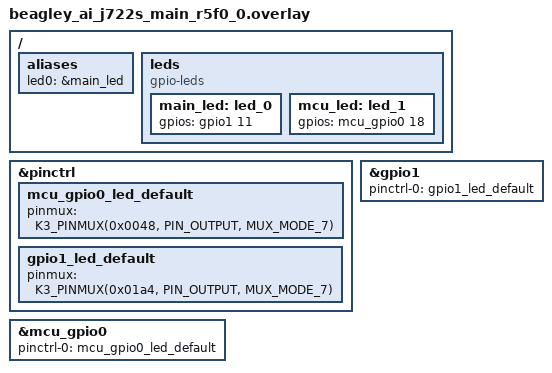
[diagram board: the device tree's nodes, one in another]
/*
 * SPDX-License-Identifier: Apache-2.0
 */

 #include <zephyr/dt-bindings/gpio/gpio.h>

 / {
	aliases {
		led0 = &main_led;
	};

	leds {
		compatible = "gpio-leds";

		main_led: led_0 {
			gpios = <&gpio1 11 GPIO_ACTIVE_HIGH>;
		};

		mcu_led: led_1 {
			gpios = <&mcu_gpio0 18 GPIO_ACTIVE_HIGH>;
		};
	};
};

&pinctrl {
	mcu_gpio0_led_default: mcu_gpio0_led_default {
		pinmux = <K3_PINMUX(0x0048, PIN_OUTPUT, MUX_MODE_7)>; /* (E11) MCU_I2C0_SDA.MCU_GPIO0_18 */
	};

	gpio1_led_default: gpio1_led_default {
		pinmux = <K3_PINMUX(0x01a4, PIN_OUTPUT, MUX_MODE_7)>; /* (D25) MCASP0_ACLKX.GPIO1_11 */
	};
};

&mcu_gpio0 {
	pinctrl-0 = <&mcu_gpio0_led_default>;
	pinctrl-names = "default";
	status = "okay";
};

&gpio1 {
	pinctrl-0 = <&gpio1_led_default>;
	pinctrl-names = "default";
	status = "okay";
};
